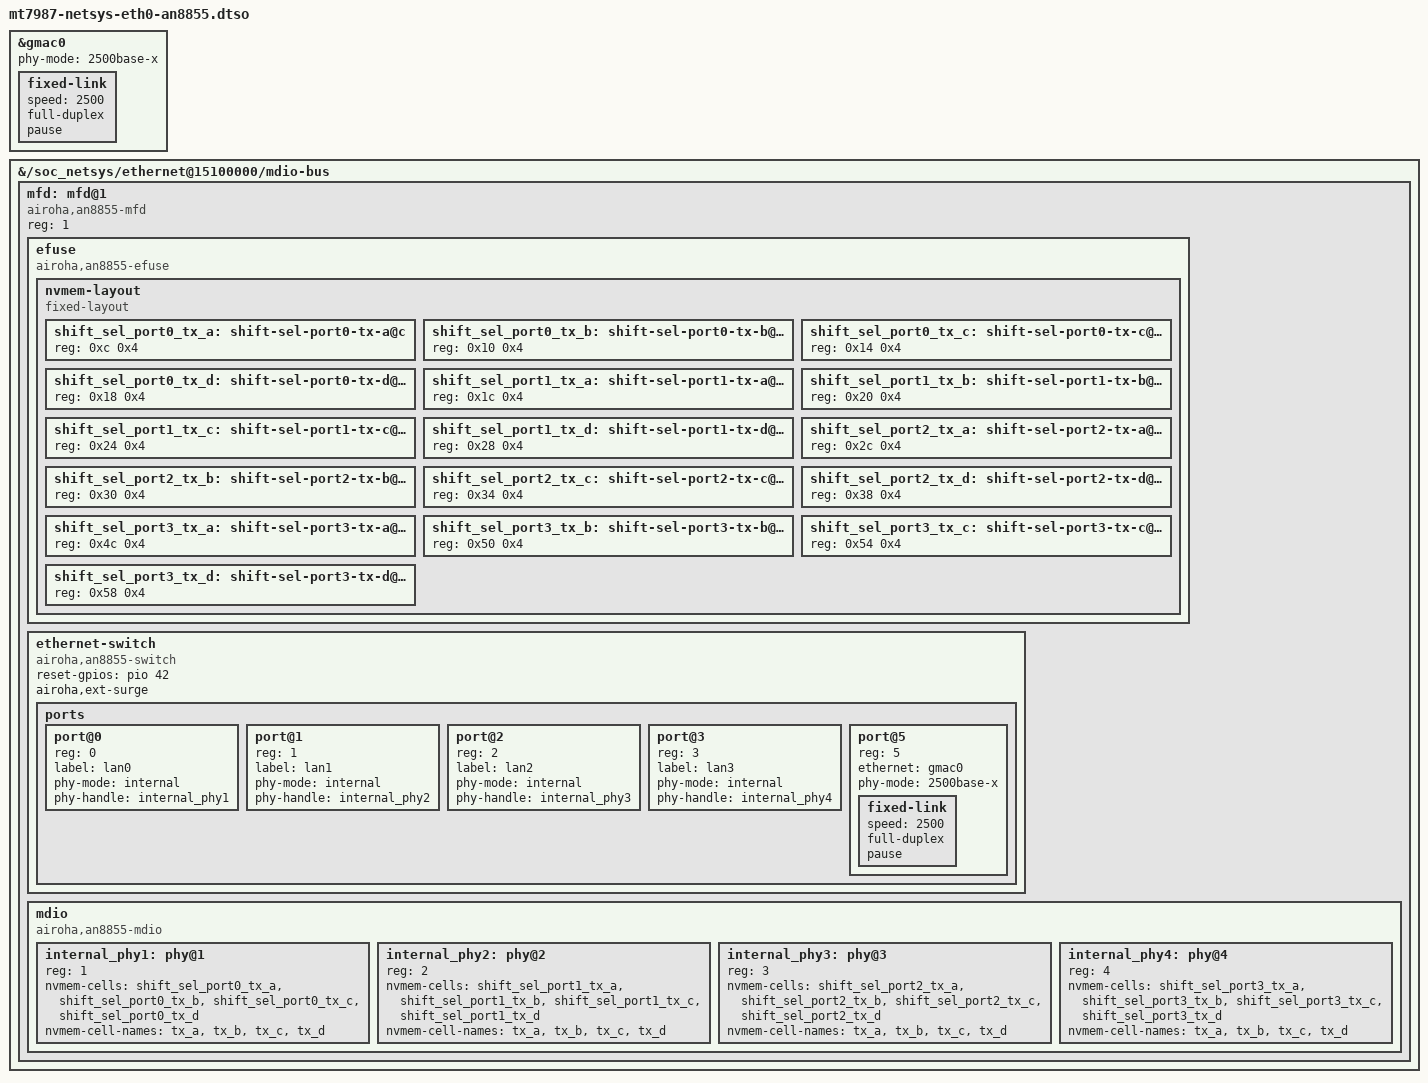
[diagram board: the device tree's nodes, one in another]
// SPDX-License-Identifier: (GPL-2.0 OR MIT)

/dts-v1/;
/plugin/;

#include <dt-bindings/gpio/gpio.h>

/ {
	fragment@0 {
		target = <&gmac0>;
		__overlay__ {
			phy-mode = "2500base-x";
			status = "okay";
			fixed-link {
				speed = <2500>;
				full-duplex;
				pause;
			};
		};

	};

	fragment@1 {
		target-path = "/soc_netsys/ethernet@15100000/mdio-bus";
		__overlay__ {
			mfd: mfd@1 {
				compatible = "airoha,an8855-mfd";
				reg = <1>;
				status = "okay";

				efuse {
					compatible = "airoha,an8855-efuse";
					#nvmem-cell-cells = <0>;

					nvmem-layout {
						compatible = "fixed-layout";
						#address-cells = <1>;
						#size-cells = <1>;

						shift_sel_port0_tx_a: shift-sel-port0-tx-a@c {
							reg = <0xc 0x4>;
						};

						shift_sel_port0_tx_b: shift-sel-port0-tx-b@10 {
							reg = <0x10 0x4>;
						};

						shift_sel_port0_tx_c: shift-sel-port0-tx-c@14 {
							reg = <0x14 0x4>;
						};

						shift_sel_port0_tx_d: shift-sel-port0-tx-d@18 {
							reg = <0x18 0x4>;
						};

						shift_sel_port1_tx_a: shift-sel-port1-tx-a@1c {
							reg = <0x1c 0x4>;
						};

						shift_sel_port1_tx_b: shift-sel-port1-tx-b@20 {
							reg = <0x20 0x4>;
						};

						shift_sel_port1_tx_c: shift-sel-port1-tx-c@24 {
							reg = <0x24 0x4>;
						};

						shift_sel_port1_tx_d: shift-sel-port1-tx-d@28 {
							reg = <0x28 0x4>;
						};

						shift_sel_port2_tx_a: shift-sel-port2-tx-a@2c {
							reg = <0x2c 0x4>;
						};

						shift_sel_port2_tx_b: shift-sel-port2-tx-b@30 {
							reg = <0x30 0x4>;
						};

						shift_sel_port2_tx_c: shift-sel-port2-tx-c@34 {
							reg = <0x34 0x4>;
						};

						shift_sel_port2_tx_d: shift-sel-port2-tx-d@38 {
							reg = <0x38 0x4>;
						};

						shift_sel_port3_tx_a: shift-sel-port3-tx-a@4c {
							reg = <0x4c 0x4>;
						};

						shift_sel_port3_tx_b: shift-sel-port3-tx-b@50 {
							reg = <0x50 0x4>;
						};

						shift_sel_port3_tx_c: shift-sel-port3-tx-c@54 {
							reg = <0x54 0x4>;
						};

						shift_sel_port3_tx_d: shift-sel-port3-tx-d@58 {
							reg = <0x58 0x4>;
						};
					};
				};

				ethernet-switch {
					compatible = "airoha,an8855-switch";
					reset-gpios = <&pio 42 GPIO_ACTIVE_HIGH>;
					airoha,ext-surge;

					ports {
						#address-cells = <1>;
						#size-cells = <0>;

						port@0 {
							reg = <0>;
							label = "lan0";
							phy-mode = "internal";
							phy-handle = <&internal_phy1>;
						};

						port@1 {
							reg = <1>;
							label = "lan1";
							phy-mode = "internal";
							phy-handle = <&internal_phy2>;
						};

						port@2 {
							reg = <2>;
							label = "lan2";
							phy-mode = "internal";
							phy-handle = <&internal_phy3>;
						};

						port@3 {
							reg = <3>;
							label = "lan3";
							phy-mode = "internal";
							phy-handle = <&internal_phy4>;
						};

						port@5 {
							reg = <5>;
							ethernet = <&gmac0>;
							phy-mode = "2500base-x";

							fixed-link {
								speed = <2500>;
								full-duplex;
								pause;
							};
						};
					};
				};

				mdio {
					compatible = "airoha,an8855-mdio";
					#address-cells = <1>;
					#size-cells = <0>;

					internal_phy1: phy@1 {
						reg = <1>;

						nvmem-cells = <&shift_sel_port0_tx_a>,
								<&shift_sel_port0_tx_b>,
								<&shift_sel_port0_tx_c>,
								<&shift_sel_port0_tx_d>;
						nvmem-cell-names = "tx_a", "tx_b", "tx_c", "tx_d";
					};

					internal_phy2: phy@2 {
						reg = <2>;

						nvmem-cells = <&shift_sel_port1_tx_a>,
								<&shift_sel_port1_tx_b>,
								<&shift_sel_port1_tx_c>,
								<&shift_sel_port1_tx_d>;
						nvmem-cell-names = "tx_a", "tx_b", "tx_c", "tx_d";
					};

					internal_phy3: phy@3 {
						reg = <3>;

						nvmem-cells = <&shift_sel_port2_tx_a>,
								<&shift_sel_port2_tx_b>,
								<&shift_sel_port2_tx_c>,
								<&shift_sel_port2_tx_d>;
						nvmem-cell-names = "tx_a", "tx_b", "tx_c", "tx_d";
					};

					internal_phy4: phy@4 {
						reg = <4>;

						nvmem-cells = <&shift_sel_port3_tx_a>,
								<&shift_sel_port3_tx_b>,
								<&shift_sel_port3_tx_c>,
								<&shift_sel_port3_tx_d>;
						nvmem-cell-names = "tx_a", "tx_b", "tx_c", "tx_d";
					};
				};
			};
		};
	};
};

